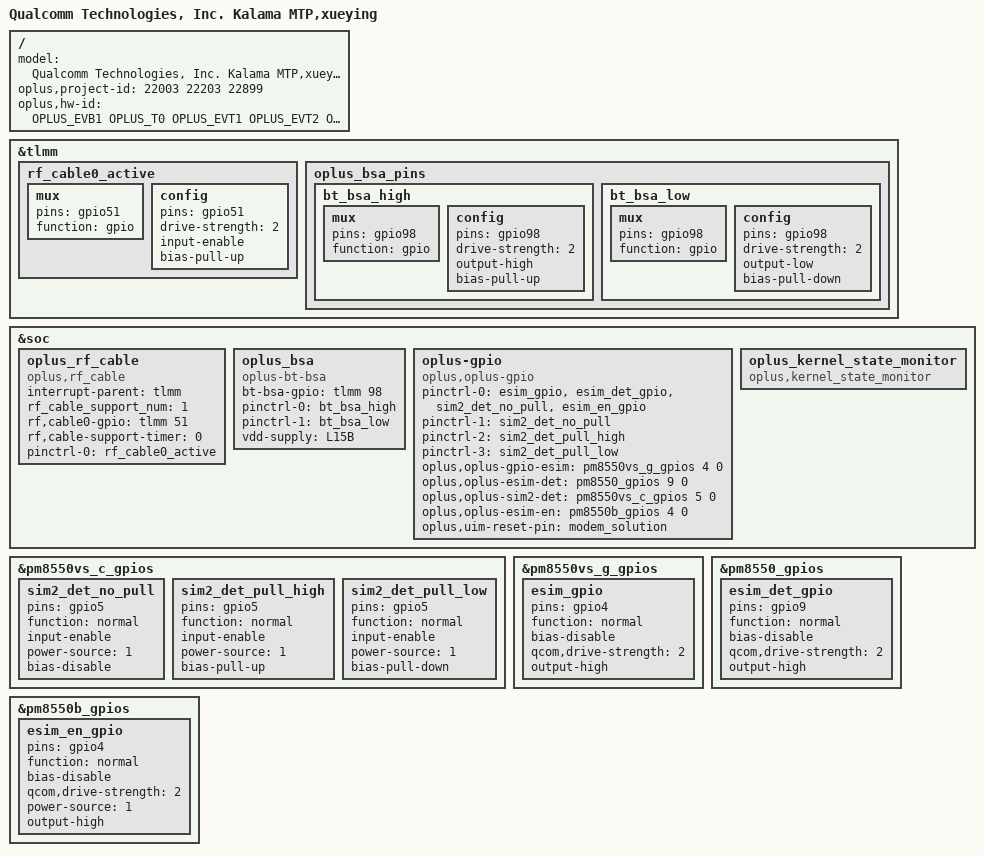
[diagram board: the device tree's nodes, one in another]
/dts-v1/;
/plugin/;
#include <dt-bindings/oplus/hw-id.h>
#include "../qcom/kalama-mtp-overlay.dts"
#include "kalama_overlay_common.dtsi"
#include "xueying_overlay_common.dtsi"
#include "oplus_chg/oplus-chg-22003.dtsi"
#include "sensor/xueying-sensor-22003.dtsi"
#include "uff_sm8550_22003.dtsi"
#include "nfc/xueying_nfc_sn220.dtsi"
#include "tp/xueying-oplus_tp-22003.dtsi"
/ {
    model = "Qualcomm Technologies, Inc. Kalama MTP,xueying";

    oplus,project-id = <22003 22203 22899>;
    oplus,hw-id = <OPLUS_EVB1 OPLUS_T0 OPLUS_EVT1 OPLUS_EVT2 OPLUS_DVT1 OPLUS_DVT2 OPLUS_PVT1 OPLUS_MP1>;
};

&tlmm {
  //#ifdef OPLUS_FEATURE_RF_CABLE_DETECT
  rf_cable0_active: rf_cable0_active {
    mux {
      pins = "gpio51";
      function = "gpio";
    };
    config {
      pins = "gpio51";
      drive-strength = <2>;
      input-enable;
      bias-pull-up;
    };
  };
  //#endif /* OPLUS_FEATURE_RF_CABLE_DETECT */

  //#ifdef OPLUS_FEATURE_BT_SMART_ANTENNA
  oplus_bsa_pins {
    bt_bsa_high: bt_bsa_high {
      mux {
        pins = "gpio98";
        function = "gpio";
      };
      config {
        pins = "gpio98";
        drive-strength = <2>;
        output-high;
        bias-pull-up;
      };
    };
    bt_bsa_low: bt_bsa_low {
      mux {
        pins = "gpio98";
        function = "gpio";
      };
      config {
        pins = "gpio98";
        drive-strength = <2>;
        output-low;
        bias-pull-down;
      };
    };
  };
  //#endif
};

&soc {
  //#ifdef OPLUS_FEATURE_RF_CABLE_DETECT
  oplus_rf_cable {
    compatible = "oplus,rf_cable";
    interrupt-parent = <&tlmm>;
    rf_cable_support_num = <1>;
    rf,cable0-gpio = <&tlmm 51 0>;
    rf,cable-support-timer = <0>;
    pinctrl-names = "rf_cable_active";
    pinctrl-0 = <&rf_cable0_active>;
  };
  //#endif /* OPLUS_FEATURE_RF_CABLE_DETECT */

  //#ifdef OPLUS_FEATURE_BT_SMART_ANTENNA
  oplus_bsa {
    compatible = "oplus-bt-bsa";
    bt-bsa-gpio = <&tlmm 98 0>;
    pinctrl-names = "bt_bsa_high", "bt_bsa_low";
    pinctrl-0 = <&bt_bsa_high>;
    pinctrl-1 = <&bt_bsa_low>;
    vdd-supply = <&L15B>;
  };
  //#endif

  //#ifdef OPLUS_FEATRUE_ESIM
  oplus-gpio {
    compatible = "oplus,oplus-gpio";
    pinctrl-names = "default", "sim2_det_no_pull", "sim2_det_pull_high", "sim2_det_pull_low";
    pinctrl-0 = <&esim_gpio &esim_det_gpio &sim2_det_no_pull &esim_en_gpio>;
    pinctrl-1 = <&sim2_det_no_pull>;
    pinctrl-2 = <&sim2_det_pull_high>;
    pinctrl-3 = <&sim2_det_pull_low>;
    oplus,oplus-gpio-esim = <&pm8550vs_g_gpios 4 0>;
    oplus,oplus-esim-det = <&pm8550_gpios 9 0>;
    oplus,oplus-sim2-det = <&pm8550vs_c_gpios 5 0>;
    oplus,oplus-esim-en = <&pm8550b_gpios 4 0>;
    oplus,uim-reset-pin = "modem_solution";
  };
  //#endif /* OPLUS_FEATRUE_ESIM */

  oplus_kernel_state_monitor {
    compatible = "oplus,kernel_state_monitor";
  };

};

//#ifdef OPLUS_FEATRUE_ESIM
&pm8550vs_c_gpios {
  sim2_det_no_pull: sim2_det_no_pull {
      pins = "gpio5";
      function = "normal";
      input-enable;
      power-source = <1>;
      bias-disable;
  };

  sim2_det_pull_high: sim2_det_pull_high {
      pins = "gpio5";
      function = "normal";
      input-enable;
      power-source = <1>;
      bias-pull-up;
  };

  sim2_det_pull_low: sim2_det_pull_low {
      pins = "gpio5";
      function = "normal";
      input-enable;
      power-source = <1>;
      bias-pull-down;
  };
};

&pm8550vs_g_gpios {
  esim_gpio: esim_gpio  {
      pins = "gpio4";
      function = "normal";
      bias-disable; /* NO pull */
      qcom,drive-strength = <2>; /* 2 MA */
      output-high;
  };
};

&pm8550_gpios {
  esim_det_gpio: esim_det_gpio {
      pins = "gpio9";
      function = "normal";
      bias-disable; /* NO pull */
      qcom,drive-strength = <2>; /* 2 MA */
      output-high;
  };
};

&pm8550b_gpios {
  esim_en_gpio: esim_en_gpio  {
      pins = "gpio4";
      function = "normal";
      bias-disable; /* NO pull */
      qcom,drive-strength = <2>; /* 2 MA */
      power-source = <1>; /* 1.8V */
      output-high;
  };
};
//#endif /* OPLUS_FEATRUE_ESIM */
